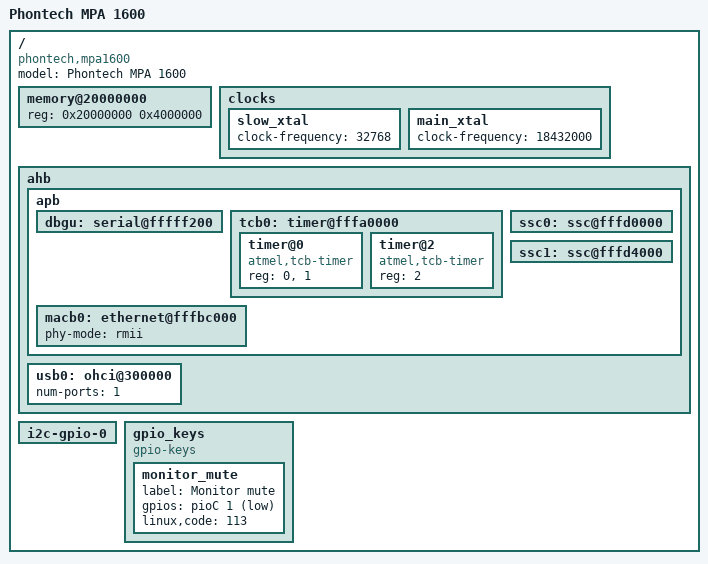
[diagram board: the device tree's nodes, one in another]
// SPDX-License-Identifier: GPL-2.0-only
/*
 * mpa1600.dts - Device Tree file for Phontech MPA 1600
 *
 *  Copyright (C) 2013 Joachim Eastwood <manabian@gmail.com>
 */
/dts-v1/;
#include "at91rm9200.dtsi"

/ {
	model = "Phontech MPA 1600";
	compatible = "phontech,mpa1600", "atmel,at91rm9200";

	memory@20000000 {
		reg = <0x20000000 0x4000000>;
	};

	clocks {
		slow_xtal {
			clock-frequency = <32768>;
		};

		main_xtal {
			clock-frequency = <18432000>;
		};
	};

	ahb {
		apb {
			dbgu: serial@fffff200 {
				status = "okay";
			};

			tcb0: timer@fffa0000 {
				timer@0 {
					compatible = "atmel,tcb-timer";
					reg = <0>, <1>;
				};

				timer@2 {
					compatible = "atmel,tcb-timer";
					reg = <2>;
				};
			};

			macb0: ethernet@fffbc000 {
				phy-mode = "rmii";
				status = "okay";
			};

			ssc0: ssc@fffd0000 {
				status = "okay";
			};

			ssc1: ssc@fffd4000 {
				status = "okay";
			};
		};

		usb0: ohci@300000 {
			num-ports = <1>;
			status = "okay";
		};
	};

	i2c-gpio-0 {
		status = "okay";
	};

	gpio_keys {
		compatible = "gpio-keys";

		monitor_mute {
			label = "Monitor mute";
			gpios = <&pioC 1 GPIO_ACTIVE_LOW>;
			linux,code = <113>;
		};
	};
};
